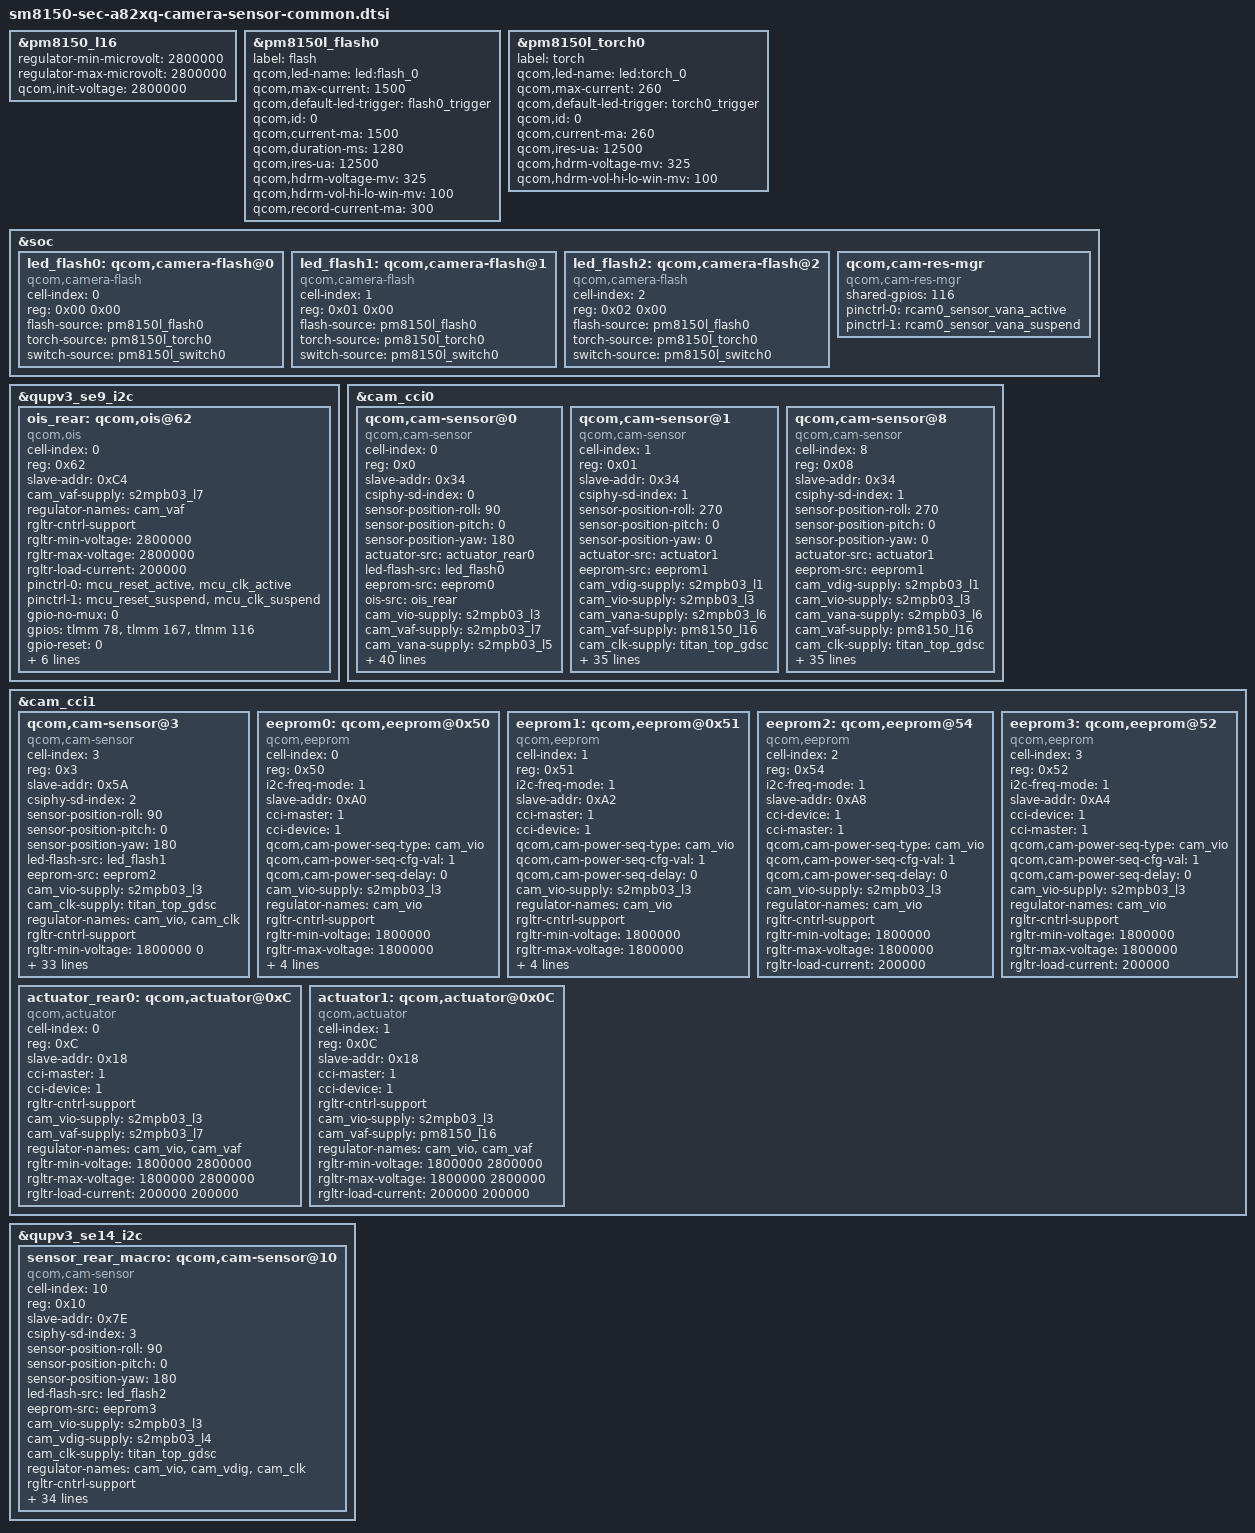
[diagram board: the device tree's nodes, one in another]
/* Copyright (c) 2020, The Linux Foundation. All rights reserved.
 *
 * This program is free software; you can redistribute it and/or modify
 * it under the terms of the GNU General Public License version 2 and
 * only version 2 as published by the Free Software Foundation.
 *
 * This program is distributed in the hope that it will be useful,
 * but WITHOUT ANY WARRANTY; without even the implied warranty of
 * MERCHANTABILITY or FITNESS FOR A PARTICULAR PURPOSE.  See the
 * GNU General Public License for more details.
 */

#include <dt-bindings/regulator/qcom,rpmh-regulator.h>

&pm8150_l16 {
	regulator-min-microvolt = <2800000>;
	regulator-max-microvolt = <2800000>;
	qcom,init-voltage = <2800000>;
};

&pm8150l_flash0 {
	label = "flash";
	qcom,led-name = "led:flash_0";
	qcom,max-current = <1500>;
	qcom,default-led-trigger = "flash0_trigger";
	qcom,id = <0>;
	qcom,current-ma = <1500>;
	qcom,duration-ms = <1280>;
	qcom,ires-ua = <12500>;
	qcom,hdrm-voltage-mv = <325>;
	qcom,hdrm-vol-hi-lo-win-mv = <100>;
	qcom,record-current-ma = <300>;
};

&pm8150l_torch0 {
	label = "torch";
	qcom,led-name = "led:torch_0";
	qcom,max-current = <260>;
	qcom,default-led-trigger = "torch0_trigger";
	qcom,id = <0>;
	qcom,current-ma = <260>;
	qcom,ires-ua = <12500>;
	qcom,hdrm-voltage-mv = <325>;
	qcom,hdrm-vol-hi-lo-win-mv = <100>;
};

&soc {
	led_flash0: qcom,camera-flash@0 {
	      cell-index = <0>;
	      reg = <0x00 0x00>;
	      compatible = "qcom,camera-flash";
	      flash-source = <&pm8150l_flash0>;
	      torch-source = <&pm8150l_torch0>;
	      switch-source = <&pm8150l_switch0>;
	      status = "ok";
	};

	led_flash1: qcom,camera-flash@1 {
	            cell-index = <1>;
	            reg = <0x01 0x00>;
	            compatible = "qcom,camera-flash";
	            flash-source = <&pm8150l_flash0>;
	            torch-source = <&pm8150l_torch0>;
	            switch-source = <&pm8150l_switch0>;
	            status = "ok";
	};

	led_flash2: qcom,camera-flash@2 {
	            cell-index = <2>;
	            reg = <0x02 0x00>;
	            compatible = "qcom,camera-flash";
	            flash-source = <&pm8150l_flash0>;
	            torch-source = <&pm8150l_torch0>;
	            switch-source = <&pm8150l_switch0>;
	            status = "ok";
	};

	qcom,cam-res-mgr {
		compatible = "qcom,cam-res-mgr";
		shared-gpios = <116>;
		pinctrl-names = "cam_res_mgr_default", "cam_res_mgr_suspend";
		status = "ok";
		pinctrl-0 = <&rcam0_sensor_vana_active>;
		pinctrl-1 = <&rcam0_sensor_vana_suspend>;
	};
};

&qupv3_se9_i2c {
    status = "ok";
    ois_rear: qcom,ois@62 {
        compatible = "qcom,ois";
        cell-index = <0>;
        reg = <0x62>;
        slave-addr = <0xC4>;

        cam_vaf-supply = <&s2mpb03_l7>;
        regulator-names = "cam_vaf";
        rgltr-cntrl-support;
        rgltr-min-voltage = <2800000>;
        rgltr-max-voltage = <2800000>;
        rgltr-load-current = <200000>;
        pinctrl-names = "cam_default", "cam_suspend";
        pinctrl-0 = <&mcu_reset_active &mcu_clk_active>;
        pinctrl-1 = <&mcu_reset_suspend &mcu_clk_suspend>;
        gpio-no-mux = <0>;
        gpios = <&tlmm 78 0>, /* RESET */
        <&tlmm 167 0>, /* BOOT0 */
        <&tlmm 116 0>; /* VDD_OIS_MCU_1P8 */

        gpio-reset = <0>;
        gpio-custom1 = <1>;
        gpio-custom2 = <2>;
        gpio-req-tbl-num = <0 1 2>;
        gpio-req-tbl-flags = <0 0 0>;
        gpio-req-tbl-label = "MCU_RESET0", "MCU_BOOT0", "MCU_VIO";
        status = "ok";
    };
};

&cam_cci0 {
    qcom,cam-sensor@0 { /* REAR CAM1 - 64MP Wide */
        cell-index = <0>;
        compatible = "qcom,cam-sensor";
        reg = <0x0>;
        slave-addr = <0x34>;
        csiphy-sd-index = <0>;
        sensor-position-roll = <90>;
        sensor-position-pitch = <0>;
        sensor-position-yaw = <180>;

        actuator-src = <&actuator_rear0>;
        led-flash-src = <&led_flash0>;
        eeprom-src = <&eeprom0>;
        ois-src = <&ois_rear>;

        // LDO
        cam_vio-supply = <&s2mpb03_l3>;
        cam_vaf-supply = <&s2mpb03_l7>;
        cam_vana-supply = <&s2mpb03_l5>;
        cam_vdig-supply = <&s2mpb03_l2>;
        cam_clk-supply = <&titan_top_gdsc>;
        regulator-names = "cam_vio","cam_vaf","cam_vana","cam_vdig","cam_clk";
        rgltr-cntrl-support;
        rgltr-min-voltage = <1800000 2800000 2900000 1100000 0>;
        rgltr-max-voltage = <1800000 2800000 2900000 1100000 0>;
        rgltr-load-current = <200000 200000 200000 200000 0>;

        // GPIO
        gpio-no-mux = <0>;
        pinctrl-names = "cam_default", "cam_suspend";
        pinctrl-0 = <&cam_sensor_mclk0_active &rcam0_sensor_reset_active>;
        pinctrl-1 = <&cam_sensor_mclk0_suspend &rcam0_sensor_reset_suspend>;

        gpios = <&tlmm 13 0>,  /* MCLK */
            <&tlmm 92 0>,     /* RST */
            <&tlmm 116 0>;     /* VANA : RCAM1_AVDD_1P8 */
        gpio-reset = <1>;
        gpio-custom1 = <2>;  //Due to multiple analog voltages :: RCAM1_AVDD_1P8
        gpio-req-tbl-num = <0 1 2>;
        gpio-req-tbl-flags = <1 0 0>;
        gpio-req-tbl-label = "CAMIF_MCLK0", "CAM_RESET0", "CAM_VANA0";

        sensor-mode = <0>;
        cci-device = <0>;
        cci-master = <0>;
        status = "ok";
        clocks = <&clock_camcc CAM_CC_MCLK0_CLK>;
        clock-names = "cam_clk";
        clock-cntl-level = "turbo";
        clock-rates = <19200000>;

        cam,isp = <0>;                  // 0 : INT , 1 : EXT , 2 : SOC
        cam,cal_memory = <2>;           // 0 : N , 1 : FROM , 2 : EEPROM , 3 : OTP
        cam,read_version = <0>;         // 0 : SYSFS , 1 : CAMON
        cam,core_voltage = <0>;         // 0 : N , 1 : Y
        cam,upgrade = <0>;              // 0 : N , 1 : SYSFS , 2 : CAMON
        cam,fw_write = <0>;             // 0 : N , 1 : OS , 2 : SD , 3 : ALL
        cam,fw_dump = <0>;              // 0 : N , 1 : Y
        cam,companion_chip = <0>;       // 0 : N , 1 : Y
        cam,ois = <1>;                  // 0 : N , 1 : Y
        cam,dual_open = <0>;            // 0 : N , 1 : Y
        cam,valid = <1>;                // 0 : N , 1 : Y
    };

    qcom,cam-sensor@1 { /*VT 10M IMX374*/
        cell-index = <1>;
        compatible = "qcom,cam-sensor";
        reg = <0x01>;
        slave-addr = <0x34>;

        csiphy-sd-index = <1>;
        sensor-position-roll = <270>;
        sensor-position-pitch = <0>;
        sensor-position-yaw = <0>;

        actuator-src = <&actuator1>;
        eeprom-src = <&eeprom1>;

        // LDO
        cam_vdig-supply = <&s2mpb03_l1>; /* VDD_VT10M_1P05 */
        cam_vio-supply = <&s2mpb03_l3>;  /* CAM_VDDIO_1P8 */
        cam_vana-supply = <&s2mpb03_l6>; /* VDD_VT10M_A2P8 */
        cam_vaf-supply = <&pm8150_l16>;  /* VDD_VT10M_AF_2P8 */
        cam_clk-supply = <&titan_top_gdsc>;
        regulator-names = "cam_vdig", "cam_vio", "cam_vana", "cam_vaf", "cam_clk";
        rgltr-cntrl-support;
        rgltr-min-voltage = <1050000 1800000 2800000 2800000 0>;
        rgltr-max-voltage = <1050000 1800000 2800000 2800000 0>;
        rgltr-load-current = <200000 200000 5000 5000 0>;

        // GPIO
        gpio-no-mux = <0>;
        //use-shared-clk;
        pinctrl-names = "cam_default", "cam_suspend";
        pinctrl-0 = <&cam_sensor_mclk1_active &fcam1_sensor_reset_active>;
        pinctrl-1 = <&cam_sensor_mclk1_suspend &fcam1_sensor_reset_suspend>;


        gpios = <&tlmm 15 0>, /* MCLK */
            <&tlmm 81 0>;   /* RST */

        gpio-reset = <1>;
        gpio-req-tbl-num = <0 1>;
        gpio-req-tbl-flags = <1 0>;
        gpio-req-tbl-label = "CAMIF_MCLK2", "CAM_RESET2";

        sensor-mode = <0>;
        cci-device = <0>;
        cci-master = <1>;
        status = "ok";
        clocks = <&clock_camcc CAM_CC_MCLK2_CLK>;
        clock-names = "cam_clk";
        clock-cntl-level = "turbo";
        clock-rates = <24000000>;

        cam,isp = <0>;                  // 0 : INT , 1 : EXT , 2 : SOC
        cam,cal_memory = <2>;           // 0 : N , 1 : FROM , 2 : EEPROM , 3 : OTP
        cam,read_version = <0>;         // 0 : SYSFS , 1 : CAMON
        cam,core_voltage = <0>;         // 0 : N , 1 : Y
        cam,upgrade = <0>;              // 0 : N , 1 : SYSFS , 2 : CAMON
        cam,fw_write = <0>;             // 0 : N , 1 : OS , 2 : SD , 3 : ALL
        cam,fw_dump = <0>;              // 0 : N , 1 : Y
        cam,companion_chip = <0>;       // 0 : N , 1 : Y
        cam,ois = <0>;                  // 0 : N , 1 : Y
        cam,dual_open = <0>;            // 0 : N , 1 : Y
        cam,valid = <1>;                // 0 : N , 1 : Y
    };

    qcom,cam-sensor@8 { /*VT 10M IMX374 FULL*/
        cell-index = <8>;
        compatible = "qcom,cam-sensor";
        reg = <0x08>;
        slave-addr = <0x34>;

        csiphy-sd-index = <1>;
        sensor-position-roll = <270>;
        sensor-position-pitch = <0>;
        sensor-position-yaw = <0>;

        actuator-src = <&actuator1>;
        eeprom-src = <&eeprom1>;

        // LDO
        cam_vdig-supply = <&s2mpb03_l1>; /* VDD_VT10M_1P05 */
        cam_vio-supply = <&s2mpb03_l3>;  /* CAM_VDDIO_1P8 */
        cam_vana-supply = <&s2mpb03_l6>; /* VDD_VT10M_A2P8 */
        cam_vaf-supply = <&pm8150_l16>;  /* VDD_VT10M_AF_2P8 */
        cam_clk-supply = <&titan_top_gdsc>;
        regulator-names = "cam_vdig", "cam_vio", "cam_vana", "cam_vaf", "cam_clk";
        rgltr-cntrl-support;
        rgltr-min-voltage = <1050000 1800000 2800000 2800000 0>;
        rgltr-max-voltage = <1050000 1800000 2800000 2800000 0>;
        rgltr-load-current = <200000 200000 5000 5000 0>;

        // GPIO
        gpio-no-mux = <0>;
        //use-shared-clk;
        pinctrl-names = "cam_default", "cam_suspend";
        pinctrl-0 = <&cam_sensor_mclk1_active &fcam1_sensor_reset_active>;
        pinctrl-1 = <&cam_sensor_mclk1_suspend &fcam1_sensor_reset_suspend>;


        gpios = <&tlmm 15 0>, /* MCLK */
            <&tlmm 81 0>;   /* RST */

        gpio-reset = <1>;
        gpio-req-tbl-num = <0 1>;
        gpio-req-tbl-flags = <1 0>;
        gpio-req-tbl-label = "CAMIF_MCLK2", "CAM_RESET2";

        sensor-mode = <0>;
        cci-device = <0>;
        cci-master = <1>;
        status = "ok";
        clocks = <&clock_camcc CAM_CC_MCLK2_CLK>;
        clock-names = "cam_clk";
        clock-cntl-level = "turbo";
        clock-rates = <24000000>;

        cam,isp = <0>;                  // 0 : INT , 1 : EXT , 2 : SOC
        cam,cal_memory = <2>;           // 0 : N , 1 : FROM , 2 : EEPROM , 3 : OTP
        cam,read_version = <0>;         // 0 : SYSFS , 1 : CAMON
        cam,core_voltage = <0>;         // 0 : N , 1 : Y
        cam,upgrade = <0>;              // 0 : N , 1 : SYSFS , 2 : CAMON
        cam,fw_write = <0>;             // 0 : N , 1 : OS , 2 : SD , 3 : ALL
        cam,fw_dump = <0>;              // 0 : N , 1 : Y
        cam,companion_chip = <0>;       // 0 : N , 1 : Y
        cam,ois = <0>;                  // 0 : N , 1 : Y
        cam,dual_open = <0>;            // 0 : N , 1 : Y
        cam,valid = <1>;                // 0 : N , 1 : Y
    };
};

&cam_cci1 {
    qcom,cam-sensor@3 { /* REAR UW CAM - 12MP UW */
        cell-index = <3>;
        compatible = "qcom,cam-sensor";
        reg = <0x3>;
        slave-addr = <0x5A>;
        csiphy-sd-index = <2>;
        sensor-position-roll = <90>;
        sensor-position-pitch = <0>;
        sensor-position-yaw = <180>;
        led-flash-src = <&led_flash1>;
        eeprom-src = <&eeprom2>;

        cam_vio-supply = <&s2mpb03_l3>;
        cam_clk-supply = <&titan_top_gdsc>;
        regulator-names =  "cam_vio", "cam_clk";
        rgltr-cntrl-support;
        rgltr-min-voltage = <1800000 0>;
        rgltr-max-voltage = <1800000 0>;
        rgltr-load-current = <200000 0>;

        gpio-no-mux = <0>;
        pinctrl-names = "cam_default", "cam_suspend";
        pinctrl-0 = <&cam_sensor_mclk2_active &rcam2_sensor_reset_active &rcam2_sensor_vana_active>;
        pinctrl-1 = <&cam_sensor_mclk2_suspend &rcam2_sensor_reset_suspend &rcam2_sensor_vana_suspend>;
        gpios = <&tlmm 14 0>, /* MCLK */
            <&tlmm 21 0>,     /* RST */
            <&tlmm 124 0>; /* VANA */

        gpio-reset = <1>;
        gpio-custom1 = <2>;
        gpio-req-tbl-num = <0 1 2>;
        gpio-req-tbl-flags = <1 0 0>;
        gpio-req-tbl-label = "CAMIF_MCLK_UW", "CAM_RESET_UW", "CAM_VANA_UW";

        sensor-mode = <0>;
        cci-device = <1>;
        cci-master = <0>;
        status = "ok";
        clocks = <&clock_camcc CAM_CC_MCLK1_CLK>;
        clock-names = "cam_clk";
        clock-cntl-level = "turbo";
        clock-rates = <19200000>;

        cam,isp = <0>;                  // 0 : INT , 1 : EXT , 2 : SOC
        cam,cal_memory = <2>;           // 0 : N , 1 : FROM , 2 : EEPROM , 3 : OTP
        cam,read_version = <0>;         // 0 : SYSFS , 1 : CAMON
        cam,core_voltage = <0>;         // 0 : N , 1 : Y
        cam,upgrade = <0>;              // 0 : N , 1 : SYSFS , 2 : CAMON
        cam,fw_write = <0>;             // 0 : N , 1 : OS , 2 : SD , 3 : ALL
        cam,fw_dump = <0>;              // 0 : N , 1 : Y
        cam,companion_chip = <0>;       // 0 : N , 1 : Y
        cam,ois = <0>;                  // 0 : N , 1 : Y
        cam,dual_open = <0>;            // 0 : N , 1 : Y
        cam,valid = <1>;
    };

    eeprom0: qcom,eeprom@0x50 {
        cell-index = <0>;
        reg = <0x50>;
        compatible = "qcom,eeprom";
        i2c-freq-mode = <1>;
        slave-addr = <0xA0>;
        //eeprom-name= "gt24p128e_imx682";

        cci-master = <1>;
        cci-device = <1>;

        qcom,cam-power-seq-type = "cam_vio";
        qcom,cam-power-seq-cfg-val = <1>;
        qcom,cam-power-seq-delay = <0>;

        cam_vio-supply = <&s2mpb03_l3>;  /* CAM_VDDIO_1P8 */
        regulator-names = "cam_vio";
        rgltr-cntrl-support;
        rgltr-min-voltage = <1800000>;
        rgltr-max-voltage = <1800000>;
        rgltr-load-current = <5000>;
        gpio-no-mux = <1>;
        sensor-position = <0>;
        sensor-mode = <0>;
        status = "ok";
    };

    eeprom1: qcom,eeprom@0x51 {
        cell-index = <1>;
        compatible = "qcom,eeprom";
        reg = <0x51>;
        i2c-freq-mode = <1>;
        slave-addr = <0xA2>;

        cci-master = <1>;
        cci-device = <1>;

        qcom,cam-power-seq-type = "cam_vio";
        qcom,cam-power-seq-cfg-val = <1>;
        qcom,cam-power-seq-delay = <0>;

        cam_vio-supply = <&s2mpb03_l3>;  /* CAM_VDDIO_1P8 */
        regulator-names = "cam_vio";
        rgltr-cntrl-support;
        rgltr-min-voltage = <1800000>;
        rgltr-max-voltage = <1800000>;
        rgltr-load-current = <5000>;
        gpio-no-mux = <1>;
        sensor-position = <0>;
        sensor-mode = <0>;
        status = "ok";
    };

    eeprom2: qcom,eeprom@54 {
        cell-index = <2>;
        compatible = "qcom,eeprom";
        reg = <0x54>;
        i2c-freq-mode = <1>;
        slave-addr = <0xA8>;
        cci-device = <1>;
        cci-master = <1>;
        qcom,cam-power-seq-type = "cam_vio";
        qcom,cam-power-seq-cfg-val = <1>;
        qcom,cam-power-seq-delay = <0>;
        cam_vio-supply = <&s2mpb03_l3>;
        regulator-names =  "cam_vio";
        rgltr-cntrl-support;
        rgltr-min-voltage = <1800000>;
        rgltr-max-voltage = <1800000>;
        rgltr-load-current = <200000>;
        status = "ok";
    };

    eeprom3: qcom,eeprom@52 {
        cell-index = <3>;
        compatible = "qcom,eeprom";
        reg = <0x52>;
        i2c-freq-mode = <1>;
        slave-addr = <0xA4>;
        cci-device = <1>;
        cci-master = <1>;
        qcom,cam-power-seq-type = "cam_vio";
        qcom,cam-power-seq-cfg-val = <1>;
        qcom,cam-power-seq-delay = <0>;
        cam_vio-supply = <&s2mpb03_l3>;
        regulator-names =  "cam_vio";
        rgltr-cntrl-support;
        rgltr-min-voltage = <1800000>;
        rgltr-max-voltage = <1800000>;
        rgltr-load-current = <200000>;
        status = "ok";
    };

    actuator_rear0: qcom,actuator@0xC {
        cell-index = <0>;
        reg = <0xC>;
        slave-addr = <0x18>;
        compatible = "qcom,actuator";
        cci-master = <1>;
        cci-device = <1>;
        rgltr-cntrl-support;
        cam_vio-supply = <&s2mpb03_l3>;
        cam_vaf-supply = <&s2mpb03_l7>;
        regulator-names = "cam_vio","cam_vaf";
        rgltr-min-voltage = <1800000 2800000>;
        rgltr-max-voltage = <1800000 2800000>;
        rgltr-load-current = <200000 200000>;
        status = "ok";
    };

    actuator1: qcom,actuator@0x0C {
        cell-index = <1>;
        reg = <0x0C>;
        slave-addr = <0x18>;
        compatible = "qcom,actuator";
        cci-master = <1>;
        cci-device = <1>;
        rgltr-cntrl-support;
        cam_vio-supply = <&s2mpb03_l3>;  /* CAM_VDDIO_1P8 */
        cam_vaf-supply = <&pm8150_l16>;  /* VDD_VT10M_AF_2P8 */
        regulator-names = "cam_vio","cam_vaf";
        rgltr-min-voltage = <1800000 2800000>;
        rgltr-max-voltage = <1800000 2800000>;
        rgltr-load-current = <200000 200000>;
        status = "ok";
    };
};

&qupv3_se14_i2c{
    status = "ok";

    sensor_rear_macro: qcom,cam-sensor@10 {  /* REAR CAM 3 - 5M Macro  */
        cell-index = <10>;
        compatible = "qcom,cam-sensor";
        reg = <0x10>;
        slave-addr = <0x7E>;
        csiphy-sd-index = <3>;
        sensor-position-roll = <90>;
        sensor-position-pitch = <0>;
        sensor-position-yaw = <180>;
        led-flash-src = <&led_flash2>;
        eeprom-src = <&eeprom3>;

        // LDO
        cam_vio-supply = <&s2mpb03_l3>;
        cam_vdig-supply = <&s2mpb03_l4>;
        cam_clk-supply = <&titan_top_gdsc>;
        regulator-names = "cam_vio", "cam_vdig", "cam_clk";
        rgltr-cntrl-support;
        rgltr-min-voltage = <1800000 1200000 0>;
        rgltr-max-voltage = <1800000 1200000 0>;
        rgltr-load-current = <200000 200000 0>;

        // GPIO
        gpio-no-mux = <0>;
        pinctrl-names = "cam_default", "cam_suspend";
        pinctrl-0 = <&cam_sensor_mclk3_active &rcam3_sensor_reset_active &rcam3_sensor_vana_active>;
        pinctrl-1 = <&cam_sensor_mclk3_suspend &rcam3_sensor_reset_suspend &rcam3_sensor_vana_suspend>;

        gpios = <&tlmm 16 0>, /* MCLK */
            <&tlmm 102 0>, /* RESET */
            <&tlmm 103 0>; /* VANA */

        gpio-reset = <1>;
        gpio-custom1 = <2>;
        gpio-req-tbl-num = <0 1 2>;
        gpio-req-tbl-flags = <1 0 0>;
        gpio-req-tbl-label = "CAMIF_MCLK3", "CAM_RESET3", "CAM_VANA3";

        sensor-mode = <0>;
        cci-device = <1>;
        cci-master = <0>;
        status = "ok";
        clocks = <&clock_camcc CAM_CC_MCLK3_CLK>;
        clock-names = "cam_clk";
        clock-cntl-level = "turbo";
        clock-rates = <24000000>;

        cam,isp = <0>;                  // 0 : INT , 1 : EXT , 2 : SOC
        cam,cal_memory = <0>;           // 0 : N , 1 : FROM , 2 : EEPROM , 3 : OTP
        cam,read_version = <0>;         // 0 : SYSFS , 1 : CAMON
        cam,core_voltage = <0>;         // 0 : N , 1 : Y
        cam,upgrade = <0>;              // 0 : N , 1 : SYSFS , 2 : CAMON
        cam,fw_write = <0>;             // 0 : N , 1 : OS , 2 : SD , 3 : ALL
        cam,fw_dump = <0>;              // 0 : N , 1 : Y
        cam,companion_chip = <0>;       // 0 : N , 1 : Y
        cam,ois = <0>;                  // 0 : N , 1 : Y
        cam,dual_open = <0>;            // 0 : N , 1 : Y
        cam,valid = <1>;                // 0 : N , 1 : Y
    };
};
